AUTOSAR XML (schema 4-0-3)
standard types defined: uint8, Boolean, UInt16, UInt32, UInt8
package /AUTOSAR_Platform/DataConstrs
  range DC_Boolean: raw 0..1
  range DC_UInt16: raw 0..65535
  range DC_UInt8: raw 0..255
package /PATAC/Facility/DataTypes/Implementation
  compu method COMPU_Boolean: 0=FALSE, 1=TRUE
  unit NoUnit: factor-si-to-unit=1, offset-si-to-unit=0
package /PATAC/MSM/ComponentTypes
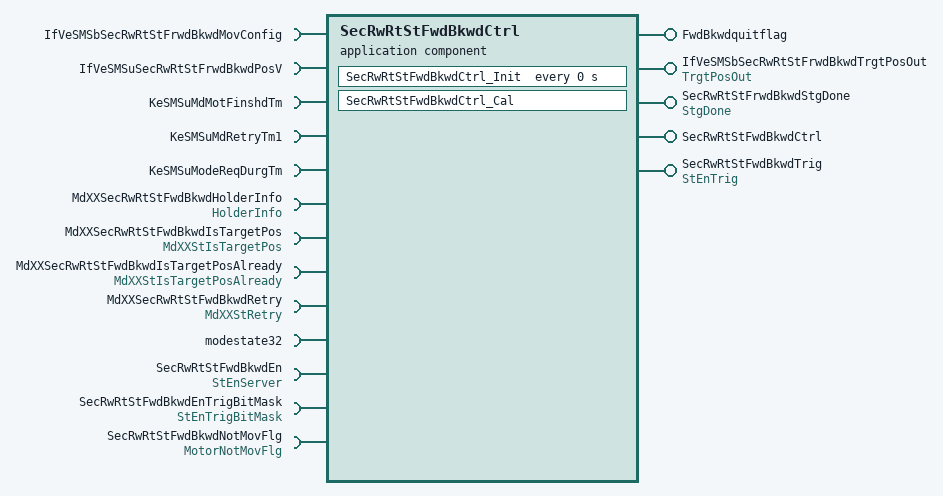
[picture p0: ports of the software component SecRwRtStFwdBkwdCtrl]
  application sw component type SecRwRtStFwdBkwdCtrl
    5 x provide port:
      FwdBkwdquitflag: nonqueued-sender-com-spec{data-element=FwdBkwdquitflag/Val, init-value=0}, provided-interface=FwdBkwdquitflag
      IfVeSMSbSecRwRtStFrwdBkwdTrgtPosOut: nonqueued-sender-com-spec{data-element=TrgtPosOut/Val, init-value=0}, provided-interface=TrgtPosOut
      SecRwRtStFrwdBkwdStgDone: nonqueued-sender-com-spec{data-element=StgDone/Val, init-value=0}, provided-interface=StgDone
      SecRwRtStFwdBkwdCtrl: server-com-spec{operation=Cal, queue-length=1}, provided-interface=SecRwRtStFwdBkwdCtrl
      SecRwRtStFwdBkwdTrig: nonqueued-sender-com-spec{data-element=StEnTrig/Val, init-value=0}, provided-interface=StEnTrig
    13 x require port:
      IfVeSMSbSecRwRtStFrwdBkwdMovConfig: nonqueued-receiver-com-spec{data-element=IfVeSMSbSecRwRtStFrwdBkwdMovConfig/Val, filter=data-filter-type=ALWAYS, init-value=0}, required-interface=IfVeSMSbSecRwRtStFrwdBkwdMovConfig
      IfVeSMSuSecRwRtStFrwdBkwdPosV: nonqueued-receiver-com-spec{data-element=IfVeSMSuSecRwRtStFrwdBkwdPosV/Val, filter=data-filter-type=ALWAYS, init-value=0}, required-interface=IfVeSMSuSecRwRtStFrwdBkwdPosV
      KeSMSuMdMotFinshdTm: parameter-require-com-spec{init-value=0, parameter=KeSMSuMdMotFinshdTm/Val}, required-interface=KeSMSuMdMotFinshdTm
      KeSMSuMdRetryTm1: parameter-require-com-spec{init-value=0, parameter=KeSMSuMdRetryTm1/Val}, required-interface=KeSMSuMdRetryTm1
      KeSMSuModeReqDurgTm: parameter-require-com-spec{init-value=0, parameter=KeSMSuModeReqDurgTm/Val}, required-interface=KeSMSuModeReqDurgTm
      MdXXSecRwRtStFwdBkwdHolderInfo: nonqueued-receiver-com-spec{data-element=HolderInfo/Val, filter=data-filter-type=ALWAYS, init-value=0}, required-interface=HolderInfo
      MdXXSecRwRtStFwdBkwdIsTargetPos: nonqueued-receiver-com-spec{data-element=MdXXStIsTargetPos/Val, filter=data-filter-type=ALWAYS, init-value=0}, required-interface=MdXXStIsTargetPos
      MdXXSecRwRtStFwdBkwdIsTargetPosAlready: nonqueued-receiver-com-spec{data-element=MdXXStIsTargetPosAlready/Val, filter=data-filter-type=ALWAYS, init-value=0}, required-interface=MdXXStIsTargetPosAlready
      MdXXSecRwRtStFwdBkwdRetry: nonqueued-receiver-com-spec{data-element=MdXXStRetry/Val, filter=data-filter-type=ALWAYS, init-value=0}, required-interface=MdXXStRetry
      modestate32: nonqueued-receiver-com-spec{data-element=modestate32/Val, filter=data-filter-type=ALWAYS, init-value=0}, required-interface=modestate32
      SecRwRtStFwdBkwdEn: required-com-specs=[Clear, Get, Set], required-interface=StEnServer
      SecRwRtStFwdBkwdEnTrigBitMask: nonqueued-receiver-com-spec{data-element=StEnTrigBitMask/Val, filter=data-filter-type=ALWAYS, init-value=0}, required-interface=StEnTrigBitMask
      SecRwRtStFwdBkwdNotMovFlg: nonqueued-receiver-com-spec{data-element=MotorNotMovFlg/Val, filter=data-filter-type=ALWAYS, init-value=0}, required-interface=MotorNotMovFlg
    behavior SecRwRtStFwdBkwdCtrl_InternalBehavior
      operation invoked event OIT_SecRwRtStFwdBkwdCtrl_Cal_SecRwRtStFwdBkwdCtrl_Cal: start-on-event=SecRwRtStFwdBkwdCtrl_Cal, operation=SecRwRtStFwdBkwdCtrl.Cal
      timing event SecRwRtStFwdBkwdCtrl_InitEvent: start-on-event=SecRwRtStFwdBkwdCtrl_Init, period=0
      runnable SecRwRtStFwdBkwdCtrl_Cal
        data-receive-point-by-arguments:
          9 x access:
            REC_IfVeSMSbSecRwRtStFrwdBkwdMovConfig_Val: accessed-variable=IfVeSMSbSecRwRtStFrwdBkwdMovConfig.Val
            REC_IfVeSMSuSecRwRtStFrwdBkwdPosV_Val: accessed-variable=IfVeSMSuSecRwRtStFrwdBkwdPosV.Val
            REC_MdXXSecRwRtStFwdBkwdHolderInfo_Val: accessed-variable=MdXXSecRwRtStFwdBkwdHolderInfo.Val
            REC_MdXXSecRwRtStFwdBkwdIsTargetPos_Val: accessed-variable=MdXXSecRwRtStFwdBkwdIsTargetPos.Val
            REC_MdXXSecRwRtStFwdBkwdIsTargetPosAlready_Val: accessed-variable=MdXXSecRwRtStFwdBkwdIsTargetPosAlready.Val
            REC_MdXXSecRwRtStFwdBkwdRetry_Val: accessed-variable=MdXXSecRwRtStFwdBkwdRetry.Val
            REC_modestate32_Val: accessed-variable=modestate32.Val
            REC_SecRwRtStFwdBkwdEnTrigBitMask_Val: accessed-variable=SecRwRtStFwdBkwdEnTrigBitMask.Val
            REC_SecRwRtStFwdBkwdNotMovFlg_Val: accessed-variable=SecRwRtStFwdBkwdNotMovFlg.Val
        data-send-points:
          4 x access:
            SEND_BkReclnquitflag_Val: accessed-variable=FwdBkwdquitflag.Val
            SEND_IfVeSMSbSecRwRtStFrwdBkwdTrgtPosOut_Val: accessed-variable=IfVeSMSbSecRwRtStFrwdBkwdTrgtPosOut.Val
            SEND_SecRwRtStFrwdBkwdStgDone_Val: accessed-variable=SecRwRtStFrwdBkwdStgDone.Val
            SEND_SecRwRtStFwdBkwdTrig_Val: accessed-variable=SecRwRtStFwdBkwdTrig.Val
        parameter access PA_KeSMSuMdMotFinshdTm_Val: accessed-parameter=KeSMSuMdMotFinshdTm.Val
        parameter access PA_KeSMSuMdRetryTm1_Val: accessed-parameter=KeSMSuMdRetryTm1.Val
        parameter access PA_KeSMSuModeReqDurgTm_Val: accessed-parameter=KeSMSuModeReqDurgTm.Val
        sync call SC_SecRwRtStFwdBkwdEn_Get: operation=SecRwRtStFwdBkwdEn.Get, timeout=0
      runnable SecRwRtStFwdBkwdCtrl_Init
        parameter access PA_KeSMSuMdMotFinshdTm_Val: accessed-parameter=KeSMSuMdMotFinshdTm.Val
        parameter access PA_KeSMSuMdRetryTm1_Val: accessed-parameter=KeSMSuMdRetryTm1.Val
        parameter access PA_KeSMSuModeReqDurgTm_Val: accessed-parameter=KeSMSuModeReqDurgTm.Val
  swc implementation SecRwRtStFwdBkwdCtrl_Implementation: behavior=SecRwRtStFwdBkwdCtrl_InternalBehavior
    code-descriptors:
      code Default: artifact-descriptors=autosar-engineering-object={short-label=Default, category=SWSRC}
package /PATAC/MSM/ModeAdjust/CalPortInterface
  parameter interface KeSMSuMdMotFinshdTm
    parameter data prototype Val: sw-calibration-access=READ-WRITE, type=UInt16
  parameter interface KeSMSuModeReqDurgTm
    parameter data prototype Val: sw-calibration-access=READ-WRITE, type=UInt16
package /PATAC/MSM/ModeAdjust/Interfaces
  sender receiver interface IfVeSMSuSecRwRtStFrwdBkwdPosV: invalidation-policy{data-element=IfVeSMSuSecRwRtStFrwdBkwdPosV/Val, handle-invalid=DONT-INVALIDATE}
    data Val: type=Boolean
package /PATAC/MSM/ModeAdjust/PortInterface
  client server interface SecRwRtStFwdBkwdCtrl
    operation Cal
  client server interface StEnServer
    operation Clear
      arg data: type=UInt8, direction=IN, server-argument-impl-policy=USE-ARGUMENT-TYPE
    operation Get
      arg data: type=UInt32, direction=OUT, server-argument-impl-policy=USE-ARGUMENT-TYPE
    operation Set
      arg data: type=UInt8, direction=IN, server-argument-impl-policy=USE-ARGUMENT-TYPE
  11 x sender receiver interface:
    FwdBkwdquitflag: invalidation-policy{data-element=FwdBkwdquitflag/Val, handle-invalid=DONT-INVALIDATE}
      data Val: type=Boolean
    HolderInfo: invalidation-policy{data-element=HolderInfo/Val, handle-invalid=DONT-INVALIDATE}
      data Val: type=UInt32
    MdXXStIsTargetPos: invalidation-policy{data-element=MdXXStIsTargetPos/Val, handle-invalid=DONT-INVALIDATE}
      data Val: type=UInt32
    MdXXStIsTargetPosAlready: invalidation-policy{data-element=MdXXStIsTargetPosAlready/Val, handle-invalid=DONT-INVALIDATE}
      data Val: type=UInt32
    MdXXStRetry: invalidation-policy{data-element=MdXXStRetry/Val, handle-invalid=DONT-INVALIDATE}
      data Val: type=UInt32
    modestate32: invalidation-policy{data-element=modestate32/Val, handle-invalid=DONT-INVALIDATE}
      data Val: type=UInt32
    MotorNotMovFlg: invalidation-policy{data-element=MotorNotMovFlg/Val, handle-invalid=DONT-INVALIDATE}
      data Val: type=Boolean
    StEnTrig: invalidation-policy{data-element=StEnTrig/Val, handle-invalid=DONT-INVALIDATE}
      data Val: type=Boolean
    StEnTrigBitMask: invalidation-policy{data-element=StEnTrigBitMask/Val, handle-invalid=DONT-INVALIDATE}
      data Val: type=UInt32
    StgDone: invalidation-policy{data-element=StgDone/Val, handle-invalid=DONT-INVALIDATE}
      data Val: type=Boolean
    TrgtPosOut: invalidation-policy{data-element=TrgtPosOut/Val, handle-invalid=DONT-INVALIDATE}
      data Val: type=Boolean
package /PATAC/MSM/PortInterfaces
  parameter interface KeSMSuMdRetryTm1
    parameter data prototype Val: sw-calibration-access=READ-WRITE, type=UInt8
  sender receiver interface IfVeSMSbSecRwRtStFrwdBkwdMovConfig: invalidation-policy{data-element=IfVeSMSbSecRwRtStFrwdBkwdMovConfig/Val, handle-invalid=DONT-INVALIDATE}
    data Val: type=Boolean
